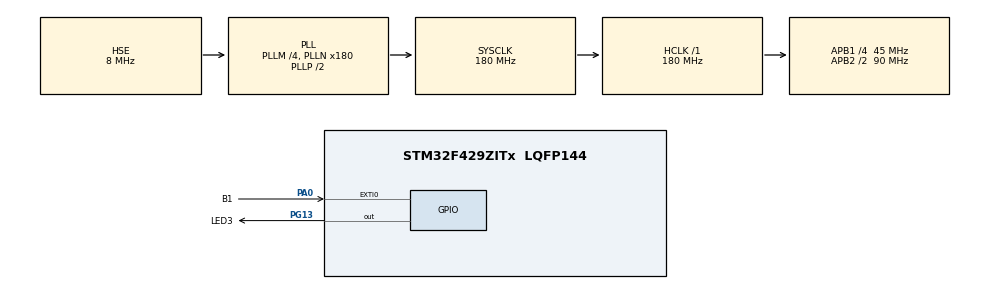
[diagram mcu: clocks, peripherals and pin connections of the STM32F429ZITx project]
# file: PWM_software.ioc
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Mcu.Family=STM32F4
Mcu.Name=STM32F429ZITx
Mcu.Package=LQFP144
NVIC.EXTI0_IRQn=true\:0\:0\:false\:true\:true\:1\:true\:true\:true
NVIC.PriorityGroup=NVIC_PRIORITYGROUP_4
NVIC.TIM2_IRQn=true\:0\:0\:false\:true\:true\:2\:true\:true\:true
PA0/WKUP.GPIO_Label=B1
PA0/WKUP.Signal=GPXTI0
PG13.GPIO_Label=LED3
PG13.GPIO_Speed=GPIO_SPEED_FREQ_HIGH
PG13.Signal=GPIO_Output
PH0/OSC_IN.Mode=HSE-External-Oscillator
PH0/OSC_IN.Signal=RCC_OSC_IN
PH1/OSC_OUT.Mode=HSE-External-Oscillator
PH1/OSC_OUT.Signal=RCC_OSC_OUT
ProjectManager.HeapSize=0x200
ProjectManager.StackSize=0x400
ProjectManager.TargetToolchain=STM32CubeIDE
RCC.48MHZClocksFreq_Value=90000000
RCC.AHBFreq_Value=180000000
RCC.APB1CLKDivider=RCC_HCLK_DIV4
RCC.APB1Freq_Value=45000000
RCC.APB1TimFreq_Value=90000000
RCC.APB2CLKDivider=RCC_HCLK_DIV2
RCC.APB2Freq_Value=90000000
RCC.APB2TimFreq_Value=180000000
RCC.CortexFreq_Value=180000000
RCC.HCLKFreq_Value=180000000
RCC.HSE_VALUE=8000000
RCC.HSI_VALUE=16000000
RCC.LSE_VALUE=32768
RCC.PLLM=4
RCC.PLLN=180
RCC.PLLSourceVirtual=RCC_PLLSOURCE_HSE
RCC.SYSCLKFreq_VALUE=180000000
RCC.SYSCLKSource=RCC_SYSCLKSOURCE_PLLCLK
RCC.VCOOutputFreq_Value=360000000
TIM2.Channel-Output\ Compare1\ No\ Output=TIM_CHANNEL_1
TIM2.Period=19999
TIM2.Prescaler=89
TIM2.Pulse-Output\ Compare1\ No\ Output=1000
VP_TIM2_VS_ClockSourceINT.Mode=Internal
VP_TIM2_VS_no_output1.Mode=Output Compare1 No Output
board=custom

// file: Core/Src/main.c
/* USER CODE BEGIN Header */
/**
  ******************************************************************************
  * @file           : main.c
  * @brief          : Main program body
  ******************************************************************************
  * @attention
  *
  * Copyright (c) 2022 STMicroelectronics.
  * All rights reserved.
  *
  * This software is licensed under terms that can be found in the LICENSE file
  * in the root directory of this software component.
  * If no LICENSE file comes with this software, it is provided AS-IS.
  *
  ******************************************************************************
  */
/* USER CODE END Header */
#include "main.h"

TIM_HandleTypeDef htim2;
TIM_OC_InitTypeDef sConfigOC;

void SystemClock_Config(void);
static void MX_GPIO_Init(void);
static void MX_TIM2_Init(void);
static void MX_NVIC_Init(void);

int main(void)
{

  /* MCU Configuration--------------------------------------------------------*/

  /* Reset of all peripherals, Initializes the Flash interface and the Systick. */
  HAL_Init();

  /* Configure the system clock */
  SystemClock_Config();

  /* Initialize all configured peripherals */
  MX_GPIO_Init();
  MX_TIM2_Init();

  /* Initialize interrupts */
  MX_NVIC_Init();
  /* USER CODE BEGIN 2 */
  HAL_TIM_Base_Start_IT(&htim2);
  HAL_TIM_OC_Start_IT(&htim2,TIM_CHANNEL_1);

  /* USER CODE END 2 */

  /* Infinite loop */
  while (1)
  {

  }
}

void SystemClock_Config(void)
{
  RCC_OscInitTypeDef RCC_OscInitStruct = {0};
  RCC_ClkInitTypeDef RCC_ClkInitStruct = {0};

  /** Configure the main internal regulator output voltage
  */
  __HAL_RCC_PWR_CLK_ENABLE();
  __HAL_PWR_VOLTAGESCALING_CONFIG(PWR_REGULATOR_VOLTAGE_SCALE1);

  /** Initializes the RCC Oscillators according to the specified parameters
  * in the RCC_OscInitTypeDef structure.
  */
  RCC_OscInitStruct.OscillatorType = RCC_OSCILLATORTYPE_HSE;
  RCC_OscInitStruct.HSEState = RCC_HSE_ON;
  RCC_OscInitStruct.PLL.PLLState = RCC_PLL_ON;
  RCC_OscInitStruct.PLL.PLLSource = RCC_PLLSOURCE_HSE;
  RCC_OscInitStruct.PLL.PLLM = 4;
  RCC_OscInitStruct.PLL.PLLN = 180;
  RCC_OscInitStruct.PLL.PLLP = RCC_PLLP_DIV2;
  RCC_OscInitStruct.PLL.PLLQ = 4;
  if (HAL_RCC_OscConfig(&RCC_OscInitStruct) != HAL_OK)
  {
    Error_Handler();
  }

  /** Activate the Over-Drive mode
  */
  if (HAL_PWREx_EnableOverDrive() != HAL_OK)
  {
    Error_Handler();
  }

  /** Initializes the CPU, AHB and APB buses clocks
  */
  RCC_ClkInitStruct.ClockType = RCC_CLOCKTYPE_HCLK|RCC_CLOCKTYPE_SYSCLK
                              |RCC_CLOCKTYPE_PCLK1|RCC_CLOCKTYPE_PCLK2;
  RCC_ClkInitStruct.SYSCLKSource = RCC_SYSCLKSOURCE_PLLCLK;
  RCC_ClkInitStruct.AHBCLKDivider = RCC_SYSCLK_DIV1;
  RCC_ClkInitStruct.APB1CLKDivider = RCC_HCLK_DIV4;
  RCC_ClkInitStruct.APB2CLKDivider = RCC_HCLK_DIV2;

  if (HAL_RCC_ClockConfig(&RCC_ClkInitStruct, FLASH_LATENCY_5) != HAL_OK)
  {
    Error_Handler();
  }
}

/**
  * @brief NVIC Configuration.
  * @retval None
  */
static void MX_NVIC_Init(void)
{
  /* EXTI0_IRQn interrupt configuration */
  HAL_NVIC_SetPriority(EXTI0_IRQn, 0, 0);
  HAL_NVIC_EnableIRQ(EXTI0_IRQn);
  /* TIM2_IRQn interrupt configuration */
  HAL_NVIC_SetPriority(TIM2_IRQn, 0, 0);
  HAL_NVIC_EnableIRQ(TIM2_IRQn);
}

static void MX_TIM2_Init(void)
{

  TIM_ClockConfigTypeDef sClockSourceConfig = {0};
  TIM_MasterConfigTypeDef sMasterConfig = {0};

  htim2.Instance = TIM2;
  htim2.Init.Prescaler = 89;
  htim2.Init.CounterMode = TIM_COUNTERMODE_UP;
  htim2.Init.Period = 19999;
  htim2.Init.ClockDivision = TIM_CLOCKDIVISION_DIV1;
  htim2.Init.AutoReloadPreload = TIM_AUTORELOAD_PRELOAD_DISABLE;
  if (HAL_TIM_Base_Init(&htim2) != HAL_OK)
  {
    Error_Handler();
  }
  sClockSourceConfig.ClockSource = TIM_CLOCKSOURCE_INTERNAL;
  if (HAL_TIM_ConfigClockSource(&htim2, &sClockSourceConfig) != HAL_OK)
  {
    Error_Handler();
  }
  if (HAL_TIM_OC_Init(&htim2) != HAL_OK)
  {
    Error_Handler();
  }
  sMasterConfig.MasterOutputTrigger = TIM_TRGO_RESET;
  sMasterConfig.MasterSlaveMode = TIM_MASTERSLAVEMODE_DISABLE;
  if (HAL_TIMEx_MasterConfigSynchronization(&htim2, &sMasterConfig) != HAL_OK)
  {
    Error_Handler();
  }
  sConfigOC.OCMode = TIM_OCMODE_TIMING;
  sConfigOC.Pulse = 500;
  sConfigOC.OCPolarity = TIM_OCPOLARITY_HIGH;
  sConfigOC.OCFastMode = TIM_OCFAST_DISABLE;
  if (HAL_TIM_OC_ConfigChannel(&htim2, &sConfigOC, TIM_CHANNEL_1) != HAL_OK)
  {
    Error_Handler();
  }

}

static void MX_GPIO_Init(void)
{
  GPIO_InitTypeDef GPIO_InitStruct = {0};

  /* GPIO Ports Clock Enable */
  __HAL_RCC_GPIOH_CLK_ENABLE();
  __HAL_RCC_GPIOA_CLK_ENABLE();
  __HAL_RCC_GPIOG_CLK_ENABLE();

  /*Configure GPIO pin Output Level */
  HAL_GPIO_WritePin(GPIOG, GPIO_PIN_13, GPIO_PIN_RESET);

  /*Configure GPIO pin : PA0 */
  GPIO_InitStruct.Pin = GPIO_PIN_0;
  GPIO_InitStruct.Mode = GPIO_MODE_IT_RISING;
  GPIO_InitStruct.Pull = GPIO_NOPULL;
  HAL_GPIO_Init(GPIOA, &GPIO_InitStruct);

  /*Configure GPIO pin : PG13 */
  GPIO_InitStruct.Pin = GPIO_PIN_13;
  GPIO_InitStruct.Mode = GPIO_MODE_OUTPUT_PP;
  GPIO_InitStruct.Pull = GPIO_NOPULL;
  GPIO_InitStruct.Speed = GPIO_SPEED_FREQ_HIGH;
  HAL_GPIO_Init(GPIOG, &GPIO_InitStruct);

}

/* USER CODE BEGIN 4 */
void HAL_TIM_PeriodElapsedCallback(TIM_HandleTypeDef *htim)
{
	//GPIO PIN OUTPUT HIGH
	if(htim->Instance==htim2.Instance)
	{
		HAL_GPIO_WritePin(GPIOG,LED3_Pin,GPIO_PIN_SET);
	}
}

void HAL_TIM_OC_DelayElapsedCallback(TIM_HandleTypeDef *htim)
{
	//GPIO PIN OUTPUT LOW
	if(htim->Instance==htim2.Instance)
		{
			HAL_GPIO_WritePin(GPIOG,LED3_Pin,GPIO_PIN_RESET);
		}
}

void HAL_GPIO_EXTI_Callback(uint16_t GPIO_Pin)
{
	if(GPIO_Pin==B1_Pin)
	{
		if(sConfigOC.Pulse>2400)
			sConfigOC.Pulse=500;
		sConfigOC.Pulse+=50;

		HAL_TIM_OC_Init(&htim2);
		HAL_TIM_OC_ConfigChannel(&htim2, &sConfigOC, TIM_CHANNEL_1);
		HAL_TIM_OC_Start_IT(&htim2,TIM_CHANNEL_1);

	}
}
/* USER CODE END 4 */

void Error_Handler(void)
{
  __disable_irq();
  while (1)
  {
  }
}
